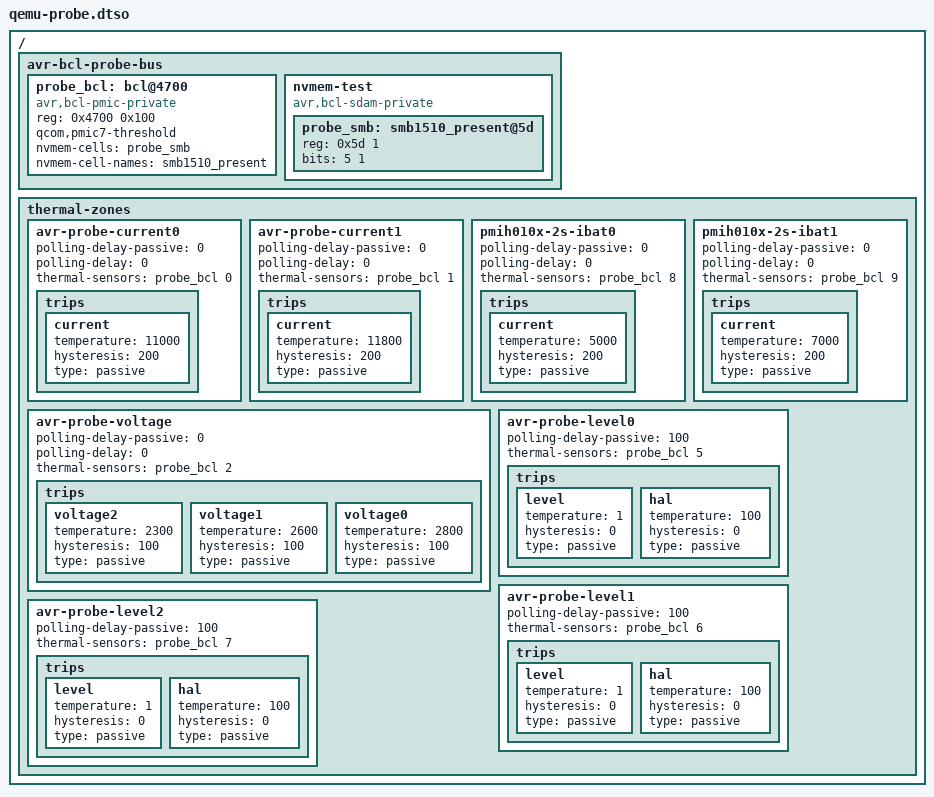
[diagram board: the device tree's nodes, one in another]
/dts-v1/;
/plugin/;
/* Private probe fixture: source IDs/thresholds/SDAM bit match AVR PMIH010x.
 * IRQ resources and register bus are supplied by the guest test, not SPMI. */
/ {
 fragment@0 {
  target-path = "/";
  __overlay__ {
   avr-bcl-probe-bus {
    #address-cells = <1>;
    #size-cells = <0>;
    probe_bcl: bcl@4700 {
     compatible = "avr,bcl-pmic-private";
     reg = <0x4700 0x100>;
     #thermal-sensor-cells = <1>;
     qcom,pmic7-threshold;
     nvmem-cells = <&probe_smb>;
     nvmem-cell-names = "smb1510_present";
    };
    nvmem-test {
     compatible = "avr,bcl-sdam-private";
     #address-cells = <1>;
     #size-cells = <1>;
     probe_smb: smb1510_present@5d { reg = <0x5d 1>; bits = <5 1>; };
    };
   };
   thermal-zones {
    avr-probe-current0 { polling-delay-passive = <0>; polling-delay = <0>; thermal-sensors = <&probe_bcl 0>; trips { current { temperature = <11000>; hysteresis = <200>; type = "passive"; }; }; };
    avr-probe-current1 { polling-delay-passive = <0>; polling-delay = <0>; thermal-sensors = <&probe_bcl 1>; trips { current { temperature = <11800>; hysteresis = <200>; type = "passive"; }; }; };
    pmih010x-2s-ibat0 { polling-delay-passive = <0>; polling-delay = <0>; thermal-sensors = <&probe_bcl 8>; trips { current { temperature = <5000>; hysteresis = <200>; type = "passive"; }; }; };
    pmih010x-2s-ibat1 { polling-delay-passive = <0>; polling-delay = <0>; thermal-sensors = <&probe_bcl 9>; trips { current { temperature = <7000>; hysteresis = <200>; type = "passive"; }; }; };
    avr-probe-voltage { polling-delay-passive = <0>; polling-delay = <0>; thermal-sensors = <&probe_bcl 2>; trips {
     voltage2 { temperature = <2300>; hysteresis = <100>; type = "passive"; };
     voltage1 { temperature = <2600>; hysteresis = <100>; type = "passive"; };
     voltage0 { temperature = <2800>; hysteresis = <100>; type = "passive"; };
    }; };
    avr-probe-level0 { polling-delay-passive = <100>; thermal-sensors = <&probe_bcl 5>; trips {
     level { temperature = <1>; hysteresis = <0>; type = "passive"; };
     hal { temperature = <100>; hysteresis = <0>; type = "passive"; };
    }; };
    avr-probe-level1 { polling-delay-passive = <100>; thermal-sensors = <&probe_bcl 6>; trips {
     level { temperature = <1>; hysteresis = <0>; type = "passive"; };
     hal { temperature = <100>; hysteresis = <0>; type = "passive"; };
    }; };
    avr-probe-level2 { polling-delay-passive = <100>; thermal-sensors = <&probe_bcl 7>; trips {
     level { temperature = <1>; hysteresis = <0>; type = "passive"; };
     hal { temperature = <100>; hysteresis = <0>; type = "passive"; };
    }; };
   };
  };
 };
};
